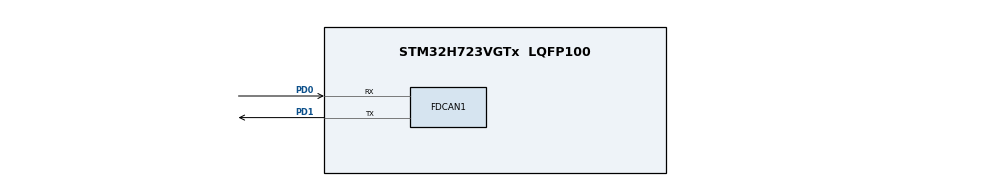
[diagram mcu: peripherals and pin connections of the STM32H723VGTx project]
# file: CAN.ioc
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CORTEX_M7.default_mode_Activation=1
FDCAN1.CalculateBaudRateNominal=1000000
FDCAN1.CalculateTimeBitNominal=1000
FDCAN1.CalculateTimeQuantumNominal=25.0
FDCAN1.DataPrescaler=3
FDCAN1.DataSyncJumpWidth=10
FDCAN1.DataTimeSeg1=29
FDCAN1.DataTimeSeg2=10
FDCAN1.NominalPrescaler=3
FDCAN1.NominalSyncJumpWidth=10
FDCAN1.NominalTimeSeg1=29
FDCAN1.NominalTimeSeg2=10
FDCAN1.ProtocolException=ENABLE
FDCAN1.RxFifo0ElmtsNbr=3
FDCAN1.StdFiltersNbr=1
FDCAN1.TxFifoQueueElmtsNbr=3
Mcu.Family=STM32H7
Mcu.Name=STM32H723VGTx
Mcu.Package=LQFP100
NVIC.FDCAN1_IT0_IRQn=true\:0\:0\:false\:false\:true\:true\:true\:true
NVIC.PriorityGroup=NVIC_PRIORITYGROUP_4
PA13(JTMS/SWDIO).Mode=Serial_Wire
PA13(JTMS/SWDIO).Signal=DEBUG_JTMS-SWDIO
PA14(JTCK/SWCLK).Mode=Serial_Wire
PA14(JTCK/SWCLK).Signal=DEBUG_JTCK-SWCLK
PD0.Mode=FDCAN_Activate
PD0.Signal=FDCAN1_RX
PD1.Mode=FDCAN_Activate
PD1.Signal=FDCAN1_TX
PH0-OSC_IN.Mode=HSE-External-Oscillator
PH0-OSC_IN.Signal=RCC_OSC_IN
PH1-OSC_OUT.Mode=HSE-External-Oscillator
PH1-OSC_OUT.Signal=RCC_OSC_OUT
ProjectManager.HeapSize=0x200
ProjectManager.StackSize=0x400
ProjectManager.TargetToolchain=CMake
RCC.ADCFreq_Value=48375000
RCC.APB1Freq_Value=120000000
RCC.APB2Freq_Value=120000000
RCC.APB3Freq_Value=120000000
RCC.APB4Freq_Value=120000000
RCC.CortexFreq_Value=480000000
RCC.D1PPRE=RCC_APB3_DIV2
RCC.D2PPRE1=RCC_APB1_DIV2
RCC.D2PPRE2=RCC_APB2_DIV2
RCC.D3PPRE=RCC_APB4_DIV2
RCC.DIVM1=2
RCC.DIVN1=40
RCC.DIVP1=1
RCC.DIVQ1=4
RCC.HCLKFreq_Value=240000000
RCC.HPRE=RCC_HCLK_DIV2
RCC.HSE_VALUE=24000000
RCC.PLLFRACN=0
RCC.PLLSourceVirtual=RCC_PLLSOURCE_HSE
RCC.SYSCLKFreq_VALUE=480000000
RCC.SYSCLKSource=RCC_SYSCLKSOURCE_PLLCLK
RCC.USBFreq_Value=120000000
VP_MEMORYMAP_VS_MEMORYMAP.Mode=CurAppReg
board=custom

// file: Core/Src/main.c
/* USER CODE BEGIN Header */
/**
  ******************************************************************************
  * @file           : main.c
  * @brief          : Main program body
  ******************************************************************************
  * @attention
  *
  * Copyright (c) 2025 STMicroelectronics.
  * All rights reserved.
  *
  * This software is licensed under terms that can be found in the LICENSE file
  * in the root directory of this software component.
  * If no LICENSE file comes with this software, it is provided AS-IS.
  *
  ******************************************************************************
  */
/* USER CODE END Header */
#include "main.h"
#include "fdcan.h"
#include "memorymap.h"
#include "gpio.h"

/* USER CODE BEGIN Includes */
#include "bsp_can.h"
#include "bsp_dwt.h"
#include "DJI_Motor.h"
#include "pid.h"
/* USER CODE END Includes */

void SystemClock_Config(void);

/* USER CODE BEGIN 0 */

#define MOTOR_SPEED_PID_KP 20.0f
#define MOTOR_SPEED_PID_KI 0.0f
#define MOTOR_SPEED_PID_KD 0.0f
#define MOTOR_SPEED_PID_IOUT_LIMIT 0.0f
#define MOTOR_SPEED_PID_OUT_LIMIT 2000.0f

PID_t Speed_PID;

/* USER CODE END 0 */

int main(void) {

    /* MCU Configuration--------------------------------------------------------*/

    /* Reset of all peripherals, Initializes the Flash interface and the Systick. */
    HAL_Init();

    /* Configure the system clock */
    SystemClock_Config();

    /* Initialize all configured peripherals */
    MX_GPIO_Init();
    MX_FDCAN1_Init();
    /* USER CODE BEGIN 2 */

    DWT_Init(480);
    FDCAN_FilterInit();

    PID_Init(&Speed_PID,
             MOTOR_SPEED_PID_OUT_LIMIT,
             MOTOR_SPEED_PID_IOUT_LIMIT,
             MOTOR_SPEED_PID_KP,
             MOTOR_SPEED_PID_KI,
             MOTOR_SPEED_PID_KD);

    dji_motor.offset_ecd = 1778;

    /* USER CODE END 2 */

    /* Infinite loop */
    while (1) {

        /* USER CODE BEGIN 3 */
        DJIMotor_Current_Set(&DJIMotor_TxFrame,
                             0,
                             0,
                             0,
                             0);

        /** 实验一：以一定转速旋转 **/
//        float target_current = PID_Calculate(&Speed_PID,
//                                             dji_motor.speed_rpm,
//                                             200);
//
//        DJIMotor_Current_Set(&DJIMotor_TxFrame,
//                             target_current,
//                             0,
//                             0,
//                             0);

        HAL_Delay(1);
    }
    /* USER CODE END 3 */
}

void SystemClock_Config(void) {
    RCC_OscInitTypeDef RCC_OscInitStruct = {0};
    RCC_ClkInitTypeDef RCC_ClkInitStruct = {0};

    /** Supply configuration update enable
    */
    HAL_PWREx_ConfigSupply(PWR_LDO_SUPPLY);

    /** Configure the main internal regulator output voltage
    */
    __HAL_PWR_VOLTAGESCALING_CONFIG(PWR_REGULATOR_VOLTAGE_SCALE0);

    while (!__HAL_PWR_GET_FLAG(PWR_FLAG_VOSRDY)) {}

    /** Initializes the RCC Oscillators according to the specified parameters
    * in the RCC_OscInitTypeDef structure.
    */
    RCC_OscInitStruct.OscillatorType = RCC_OSCILLATORTYPE_HSE;
    RCC_OscInitStruct.HSEState = RCC_HSE_ON;
    RCC_OscInitStruct.PLL.PLLState = RCC_PLL_ON;
    RCC_OscInitStruct.PLL.PLLSource = RCC_PLLSOURCE_HSE;
    RCC_OscInitStruct.PLL.PLLM = 2;
    RCC_OscInitStruct.PLL.PLLN = 40;
    RCC_OscInitStruct.PLL.PLLP = 1;
    RCC_OscInitStruct.PLL.PLLQ = 4;
    RCC_OscInitStruct.PLL.PLLR = 2;
    RCC_OscInitStruct.PLL.PLLRGE = RCC_PLL1VCIRANGE_3;
    RCC_OscInitStruct.PLL.PLLVCOSEL = RCC_PLL1VCOWIDE;
    RCC_OscInitStruct.PLL.PLLFRACN = 0;
    if (HAL_RCC_OscConfig(&RCC_OscInitStruct) != HAL_OK) {
        Error_Handler();
    }

    /** Initializes the CPU, AHB and APB buses clocks
    */
    RCC_ClkInitStruct.ClockType = RCC_CLOCKTYPE_HCLK | RCC_CLOCKTYPE_SYSCLK
                                  | RCC_CLOCKTYPE_PCLK1 | RCC_CLOCKTYPE_PCLK2
                                  | RCC_CLOCKTYPE_D3PCLK1 | RCC_CLOCKTYPE_D1PCLK1;
    RCC_ClkInitStruct.SYSCLKSource = RCC_SYSCLKSOURCE_PLLCLK;
    RCC_ClkInitStruct.SYSCLKDivider = RCC_SYSCLK_DIV1;
    RCC_ClkInitStruct.AHBCLKDivider = RCC_HCLK_DIV2;
    RCC_ClkInitStruct.APB3CLKDivider = RCC_APB3_DIV2;
    RCC_ClkInitStruct.APB1CLKDivider = RCC_APB1_DIV2;
    RCC_ClkInitStruct.APB2CLKDivider = RCC_APB2_DIV2;
    RCC_ClkInitStruct.APB4CLKDivider = RCC_APB4_DIV2;

    if (HAL_RCC_ClockConfig(&RCC_ClkInitStruct, FLASH_LATENCY_3) != HAL_OK) {
        Error_Handler();
    }
}

void Error_Handler(void) {
    __disable_irq();
    while (1) {
    }
}
